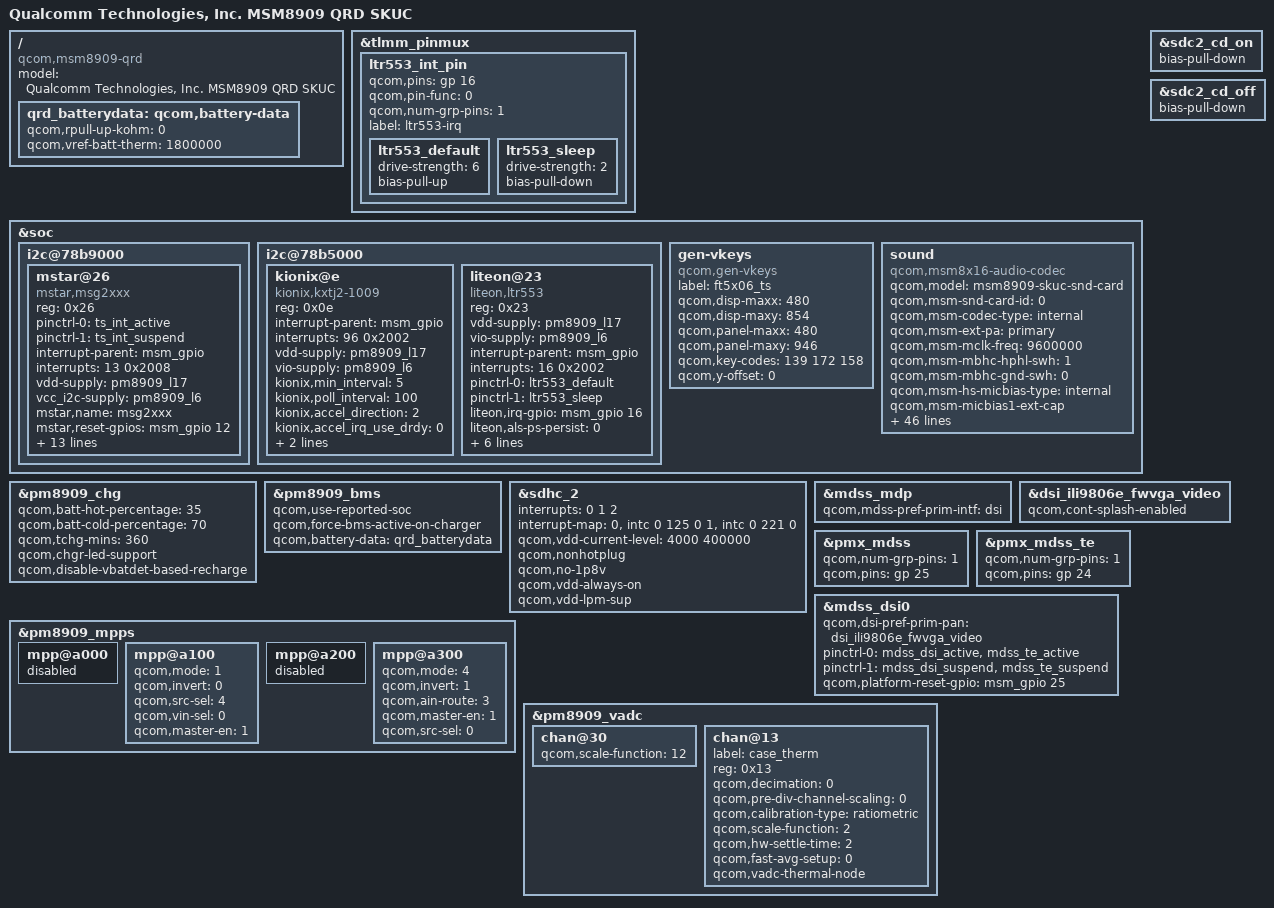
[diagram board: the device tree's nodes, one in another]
/* Copyright (c) 2014-2015, The Linux Foundation. All rights reserved.
 *
 * This program is free software; you can redistribute it and/or modify
 * it under the terms of the GNU General Public License version 2 and
 * only version 2 as published by the Free Software Foundation.
 *
 * This program is distributed in the hope that it will be useful,
 * but WITHOUT ANY WARRANTY; without even the implied warranty of
 * MERCHANTABILITY or FITNESS FOR A PARTICULAR PURPOSE.  See the
 * GNU General Public License for more details.
 */

#include "msm8909-camera-sensor-a16c3h.dtsi"
#include "dsi-panel-ili9806e-fwvga-video.dtsi"
#include "dsi-panel-ili9806e-fwvga-hsd-helitai-video.dtsi"
#include "dsi-panel-ili9806e-fwvga_hsd_huashi-video.dtsi"

/ {
	model = "Qualcomm Technologies, Inc. MSM8909 QRD SKUC";
	compatible = "qcom,msm8909-qrd", "qcom,msm8909", "qcom,qrd";
};

&tlmm_pinmux {
	ltr553_int_pin {
		qcom,pins = <&gp 16>;
		qcom,pin-func = <0>;
		qcom,num-grp-pins = <1>;
		label = "ltr553-irq";
		ltr553_default: ltr553_default {
			drive-strength = <6>;
			bias-pull-up;
		};
		ltr553_sleep: ltr553_sleep {
			drive-strength = <2>;
			bias-pull-down;
		};
	};
};

&soc {
	i2c@78b9000 { /* BLSP1 QUP5 */
		mstar@26{
			compatible = "mstar,msg2xxx";
			reg = <0x26>;
                     	pinctrl-names = "pmx_ts_int_active","pmx_ts_int_suspend"; 
                     	pinctrl-0 = <&ts_int_active>; 
                     	pinctrl-1 = <&ts_int_suspend>;
			interrupt-parent = <&msm_gpio>;
			interrupts = <13 0x2008>;
			vdd-supply = <&pm8909_l17>;
			vcc_i2c-supply = <&pm8909_l6>;

			mstar,name = "msg2xxx";			
			mstar,reset-gpios = <&msm_gpio 12 0x0>;
			mstar,interrupt-gpios = <&msm_gpio 13 0x2008>;	
			mstar,panel-coords = <0 0 480 954>;
			mstar,display-coords = <0 0 480 854>;
			mstar,button-map= <158 172 139>;
			mstar,no-force-update;
			mstar,i2c-pull-up;
			mstar,family-id = <0x0>;	

			mstar,disp-maxx = <480>;
			mstar,disp-maxy = <854>;
			mstar,pan-maxx = <480>;
			mstar,pan-maxy = <954>;
			mstar,key-codes = <158 172 139>;
			mstar,y-offset = <0>;
			/*label = "ms-msg2238,Mstar-TS";*/
		};
	};

	i2c@78b5000 { /* BLSP1 QUP1 */
		kionix@e {
			compatible = "kionix,kxtj2-1009";
			reg = <0x0e>;
			interrupt-parent = <&msm_gpio>;
			interrupts = <96 0x2002>;
			vdd-supply = <&pm8909_l17>;
			vio-supply = <&pm8909_l6>;
			kionix,min_interval = <5>;
			kionix,poll_interval = <100>;
			kionix,accel_direction = <2>;
			kionix,accel_irq_use_drdy = <0>;
			kionix,accel_res = <12>;
			kionix,accel_g_range = <2>;
		};

		liteon@23 {
			compatible = "liteon,ltr553";
			reg = <0x23>;
			vdd-supply = <&pm8909_l17>;
			vio-supply = <&pm8909_l6>;
			interrupt-parent = <&msm_gpio>;
			interrupts = <16 0x2002>;
			pinctrl-names = "default","sleep";
			pinctrl-0 = <&ltr553_default>;
			pinctrl-1 = <&ltr553_sleep>;
			liteon,irq-gpio = <&msm_gpio 16 0x2002>;
			liteon,als-ps-persist = <0>;
			liteon,ps-led = <0x7f>;
			liteon,ps-pulses = <4>;
			liteon,wakeup-threshold = <4>;
			liteon,als-integration-time = <0>;
			liteon,ps-distance-table = <1376 566 343 287 200 170 155>;
		};
	};

	gen-vkeys {
		compatible = "qcom,gen-vkeys";
		label = "ft5x06_ts";
		qcom,disp-maxx = <480>;
		qcom,disp-maxy = <854>;
		qcom,panel-maxx = <480>;
		qcom,panel-maxy = <946>;
		qcom,key-codes = <139 172 158>;
		qcom,y-offset = <0>;
	};

	sound {
		compatible = "qcom,msm8x16-audio-codec";
		qcom,model = "msm8909-skuc-snd-card";
		qcom,msm-snd-card-id = <0>;
		qcom,msm-codec-type = "internal";
		qcom,msm-ext-pa = "primary";
		qcom,msm-mclk-freq = <9600000>;
		qcom,msm-mbhc-hphl-swh = <1>;
		qcom,msm-mbhc-gnd-swh = <0>;
		qcom,msm-hs-micbias-type = "internal";
		qcom,msm-micbias1-ext-cap;
		qcom,msm-micbias2-ext-cap;
		qcom,audio-routing =
			"RX_BIAS", "MCLK",
			"SPK_RX_BIAS", "MCLK",
			"INT_LDO_H", "MCLK",
			"MIC BIAS Internal1", "Handset Mic",
			"MIC BIAS Internal2", "Headset Mic",
			"MIC BIAS Internal3", "Secondary Mic",
			"AMIC1", "MIC BIAS Internal1",
			"AMIC2", "MIC BIAS Internal2",
			"AMIC3", "MIC BIAS Internal3";
		pinctrl-names = "cdc_lines_act",
				"cdc_lines_sus";
		pinctrl-0 = <&cdc_pdm_lines_act>;
		pinctrl-1 = <&cdc_pdm_lines_sus>;
		asoc-platform = <&pcm0>, <&pcm1>, <&voip>, <&voice>,
				<&loopback>, <&compress>, <&hostless>,
				<&afe>, <&lsm>, <&routing>, <&lpa>,
				<&voice_svc>;
		asoc-platform-names = "msm-pcm-dsp.0", "msm-pcm-dsp.1",
				"msm-voip-dsp", "msm-pcm-voice", "msm-pcm-loopback",
				"msm-compress-dsp", "msm-pcm-hostless", "msm-pcm-afe",
				"msm-lsm-client", "msm-pcm-routing", "msm-pcm-lpa",
				"msm-voice-svc";
		asoc-cpu = <&dai_pri_auxpcm>, <&dai_hdmi>,
				<&dai_mi2s0>, <&dai_mi2s1>, <&dai_mi2s2>, <&dai_mi2s3>,
				<&sb_0_rx>, <&sb_0_tx>, <&sb_1_rx>, <&sb_1_tx>,
				<&sb_3_rx>, <&sb_3_tx>, <&sb_4_rx>, <&sb_4_tx>,
				<&bt_sco_rx>, <&bt_sco_tx>, <&bt_a2dp_rx>,
				<&int_fm_rx>, <&int_fm_tx>,
				<&afe_pcm_rx>, <&afe_pcm_tx>, <&afe_proxy_rx>, <&afe_proxy_tx>,
				<&incall_record_rx>, <&incall_record_tx>, <&incall_music_rx>,
				<&incall_music_2_rx>;
		asoc-cpu-names = "msm-dai-q6-auxpcm.1", "msm-dai-q6-hdmi.8",
				"msm-dai-q6-mi2s.0", "msm-dai-q6-mi2s.1",
				"msm-dai-q6-mi2s.2", "msm-dai-q6-mi2s.3",
				"msm-dai-q6-dev.16384", "msm-dai-q6-dev.16385",
				"msm-dai-q6-dev.16386", "msm-dai-q6-dev.16387",
				"msm-dai-q6-dev.16390", "msm-dai-q6-dev.16391",
				"msm-dai-q6-dev.16392", "msm-dai-q6-dev.16393",
				"msm-dai-q6-dev.12288", "msm-dai-q6-dev.12289",
				"msm-dai-q6-dev.12290", "msm-dai-q6-dev.12292",
				"msm-dai-q6-dev.12293",	"msm-dai-q6-dev.224",
				"msm-dai-q6-dev.225", "msm-dai-q6-dev.241",
				"msm-dai-q6-dev.240", "msm-dai-q6-dev.32771",
				"msm-dai-q6-dev.32772", "msm-dai-q6-dev.32773",
				"msm-dai-q6-dev.32770";
		asoc-codec = <&stub_codec>, <&pm8909_conga_dig>;
		asoc-codec-names = "msm-stub-codec.1", "tombak_codec";
	};
};

&pm8909_chg {
	qcom,batt-hot-percentage = <35>;
	qcom,batt-cold-percentage = <70>;
	qcom,tchg-mins = <360>;
	qcom,chgr-led-support;
	qcom,disable-vbatdet-based-recharge;
	status = "okay";
};

/ {
	qrd_batterydata: qcom,battery-data {
		qcom,rpull-up-kohm = <0>;
		qcom,vref-batt-therm = <1800000>;

		#include "batterydata-tmb-4v35-1900mah.dtsi"
	};
};

&pm8909_bms {
	status = "okay";
	qcom,use-reported-soc;
	qcom,force-bms-active-on-charger;
	qcom,battery-data = <&qrd_batterydata>;
};

&sdc2_cd_on {
	/delete-property/ bias-pull-up;
	bias-pull-down;
};

&sdc2_cd_off {
	/delete-property/ bias-disable;
	bias-pull-down;
};

&sdhc_2 {
	interrupts = <0 1 2>;
	interrupt-map = <0 &intc 0 125 0
		1 &intc 0 221 0>;
	interrupt-names = "hc_irq", "pwr_irq";
	qcom,vdd-current-level = <4000 400000>;
	/delete-property/ cd-gpios;
	qcom,nonhotplug;
	qcom,no-1p8v;
	qcom,vdd-always-on;
	qcom,vdd-lpm-sup;
};

&pm8909_mpps {
	mpp@a000 { /* MPP 1 */
		/* VDD_PX */
		status = "disabled";
	};

	mpp@a100 { /* MPP 2 */
		/* Backlight PWM */
		qcom,mode = <1>;		/* Digital output */
		qcom,invert = <0>;		/* Disable invert */
		qcom,src-sel = <4>;		/* DTEST1 */
		qcom,vin-sel = <0>;		/* VPH_PWR */
		qcom,master-en = <1>;		/* Enable MPP */
	};

	mpp@a200 { /* MPP 3 */
		/* VREF DAC */
		status = "disabled";
	};

	mpp@a300 { /* MPP 4 */
		 /* PA_THERM config */
		 qcom,mode = <4>; /* AIN input */
		 qcom,invert = <1>; /* Enable MPP */
		 qcom,ain-route = <3>; /* AMUX 8 */
		 qcom,master-en = <1>;
		 qcom,src-sel = <0>; /* Function constant */
	};
};

&mdss_mdp {
	qcom,mdss-pref-prim-intf = "dsi";
};

&dsi_ili9806e_fwvga_video {
	qcom,cont-splash-enabled;
};

&pmx_mdss {
	qcom,num-grp-pins = <1>;
	qcom,pins = <&gp 25>;
};

&pmx_mdss_te {
	qcom,num-grp-pins = <1>;
	qcom,pins = <&gp 24>;
};

&mdss_dsi0 {
	qcom,dsi-pref-prim-pan = <&dsi_ili9806e_fwvga_video>;
	pinctrl-names = "mdss_default", "mdss_sleep";
	pinctrl-0 = <&mdss_dsi_active &mdss_te_active>;
	pinctrl-1 = <&mdss_dsi_suspend &mdss_te_suspend>;

	qcom,platform-reset-gpio = <&msm_gpio 25 0>;
};

&pm8909_vadc {
	chan@30 {
		qcom,scale-function = <12>;
	};

	chan@13 {
		label = "case_therm";
		reg = <0x13>;
		qcom,decimation = <0>;
		qcom,pre-div-channel-scaling = <0>;
		qcom,calibration-type = "ratiometric";
		qcom,scale-function = <2>;
		qcom,hw-settle-time = <2>;
		qcom,fast-avg-setup = <0>;
		qcom,vadc-thermal-node;
	};
};
